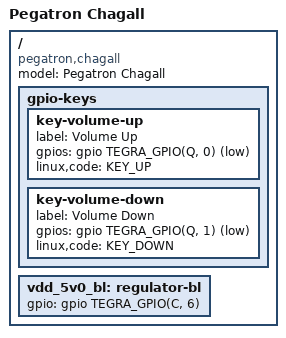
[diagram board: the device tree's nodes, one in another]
// SPDX-License-Identifier: GPL-2.0-or-later
/dts-v1/;

#include "tegra30-asus-transformer.dtsi"

/ {
	model = "Pegatron Chagall";
	compatible = "pegatron,chagall", "nvidia,tegra30";

	gpio-keys {
		key-volume-up {
			label = "Volume Up";
			gpios = <&gpio TEGRA_GPIO(Q, 0) GPIO_ACTIVE_LOW>;
			linux,code = <KEY_UP>;
		};

		key-volume-down {
			label = "Volume Down";
			gpios = <&gpio TEGRA_GPIO(Q, 1) GPIO_ACTIVE_LOW>;
			linux,code = <KEY_DOWN>;
		};
	};

	vdd_5v0_bl: regulator-bl {
		gpio = <&gpio TEGRA_GPIO(C, 6) GPIO_ACTIVE_HIGH>;
	};
};
